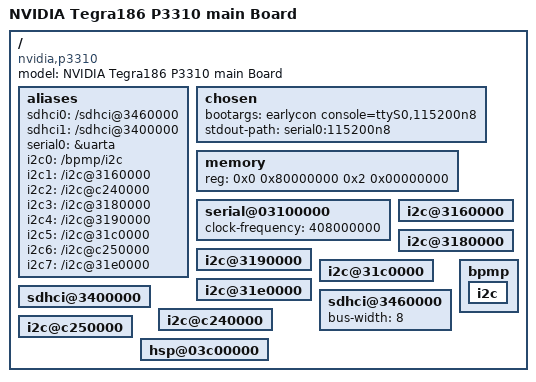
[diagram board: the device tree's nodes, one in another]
#include "tegra186.dtsi"

/ {
	model = "NVIDIA Tegra186 P3310 main Board";
	compatible = "nvidia,p3310", "nvidia,tegra186";

	aliases {
		sdhci0 = "/sdhci@3460000";
		sdhci1 = "/sdhci@3400000";
		serial0 = &uarta;
		i2c0 = "/bpmp/i2c";
		i2c1 = "/i2c@3160000";
		i2c2 = "/i2c@c240000";
		i2c3 = "/i2c@3180000";
		i2c4 = "/i2c@3190000";
		i2c5 = "/i2c@31c0000";
		i2c6 = "/i2c@c250000";
		i2c7 = "/i2c@31e0000";
	};

	chosen {
		bootargs = "earlycon console=ttyS0,115200n8";
		stdout-path = "serial0:115200n8";
	};

	memory {
		device_type = "memory";
		reg = <0x0 0x80000000 0x2 0x00000000>;
	};

	serial@03100000 {
		// HACK: before clk driver ready
		clock-frequency = <408000000>;
		status = "okay";
	};

	i2c@3160000 {
		status = "okay";
	};

	i2c@3180000 {
		status = "okay";
	};

	i2c@3190000 {
		status = "okay";
	};

	i2c@31c0000 {
		status = "okay";
	};

	i2c@31e0000 {
		status = "okay";
	};

	sdhci@3400000 {
		status = "okay";
	};

	sdhci@3460000 {
		status = "okay";
		bus-width = <8>;
	};

	i2c@c240000 {
		status = "okay";
	};

	i2c@c250000 {
		status = "okay";
	};

	hsp@03c00000 {
		status = "okay";
	};

	bpmp {
		i2c {
			status = "okay";
		};
	};
};
